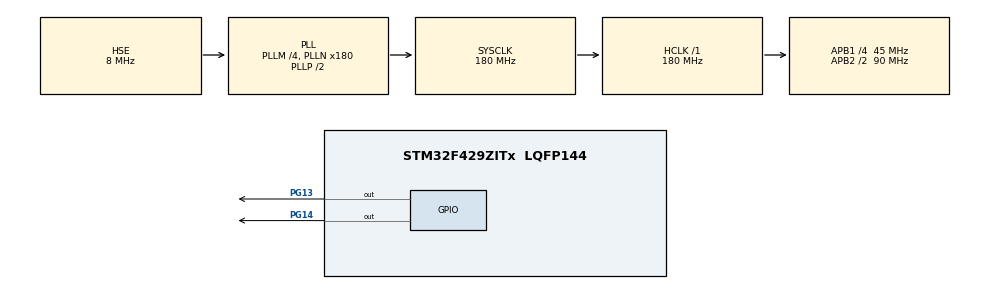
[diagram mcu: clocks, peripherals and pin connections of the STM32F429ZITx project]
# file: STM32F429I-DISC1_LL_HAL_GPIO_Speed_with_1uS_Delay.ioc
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Mcu.Family=STM32F4
Mcu.Name=STM32F429ZITx
Mcu.Package=LQFP144
NVIC.PriorityGroup=NVIC_PRIORITYGROUP_0
PG13.GPIO_Speed=GPIO_SPEED_FREQ_VERY_HIGH
PG13.Signal=GPIO_Output
PG14.GPIO_Speed=GPIO_SPEED_FREQ_VERY_HIGH
PG14.Signal=GPIO_Output
PH0/OSC_IN.Mode=HSE-External-Oscillator
PH0/OSC_IN.Signal=RCC_OSC_IN
PH1/OSC_OUT.Mode=HSE-External-Oscillator
PH1/OSC_OUT.Signal=RCC_OSC_OUT
ProjectManager.HeapSize=0x200
ProjectManager.StackSize=0x400
ProjectManager.TargetToolchain=STM32CubeIDE
RCC.48MHZClocksFreq_Value=51428571.428571425
RCC.AHBFreq_Value=180000000
RCC.APB1CLKDivider=RCC_HCLK_DIV4
RCC.APB1Freq_Value=45000000
RCC.APB1TimFreq_Value=90000000
RCC.APB2CLKDivider=RCC_HCLK_DIV2
RCC.APB2Freq_Value=90000000
RCC.APB2TimFreq_Value=180000000
RCC.CortexFreq_Value=180000000
RCC.HCLKFreq_Value=180000000
RCC.HSE_VALUE=8000000
RCC.HSI_VALUE=16000000
RCC.LSE_VALUE=32768
RCC.PLLM=4
RCC.PLLN=180
RCC.PLLQ=7
RCC.PLLSourceVirtual=RCC_PLLSOURCE_HSE
RCC.SYSCLKFreq_VALUE=180000000
RCC.SYSCLKSource=RCC_SYSCLKSOURCE_PLLCLK
RCC.VCOOutputFreq_Value=360000000
board=STM32F429I-DISC1

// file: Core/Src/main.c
/* USER CODE BEGIN Header */
/**
  ******************************************************************************
  * @file           : main.c
  * @brief          : Main program body
  ******************************************************************************
  * @attention
  *
  * <h2><center>&copy; Copyright (c) Victor.T Electronics.
  * All rights reserved.</center></h2>
  *
  * This software component is licensed by VT under BSD 3-Clause license,
  * the "License"; You may not use this file except in compliance with the
  * License. You may obtain a copy of the License at:
  *                        opensource.org/licenses/BSD-3-Clause
  *
  ******************************************************************************
  */
/* USER CODE END Header */
#include "main.h"

void SystemClock_Config(void);
static void MX_GPIO_Init(void);

int main(void)
{

  /* MCU Configuration--------------------------------------------------------*/

  /* Reset of all peripherals, Initializes the Flash interface and the Systick. */
  HAL_Init();

  /* Configure the system clock */
  SystemClock_Config();

  /* Initialize all configured peripherals */
  MX_GPIO_Init();

  /* Infinite loop */
  /* USER CODE BEGIN WHILE */
  while (1)
  {
	  // HAL
	  // 1.98Mhz / 510nS
	  // HAL_GPIO_TogglePin(GPIOG, GPIO_PIN_13); //

	  // LL
	  // 2.43Mhz / 412nS
	  // LL_GPIO_TogglePin(GPIOG, GPIO_PIN_13); //

	  // 15.1MHZ = LL/HAL / 66.8nS

	  GPIOG->BSRR = (1<<13); // SET
	  GPIOG->BSRR = (1<<29); // RESET

	  // approx 0 = 83nS, 1 = 184nS, 2 = 250nS, 3 = 317nS, 4 = 384nS, 5 = 450nS
	  // 6 = 517nS
//	  for(uint16_t nS_100 = 0; nS_100 < 1; nS_100++) // (1) (150 - 34n)S; (2) (217 - 34)nS; (3) (284 - 34)nS
//		  {}

	  // 1.018uS
	  for(uint16_t nS_100 = 0; nS_100 < 1; nS_100++) // (1) (150 - 34n)S; (2) (217 - 34)nS; (3) (284 - 34)nS
		  {}
	  for(uint16_t uS = 0; uS < 1; uS++)
	  {
		  for(uint16_t i = 0; i < 10; i++)
		  {}
	  }

    /* USER CODE END WHILE */

  }
}

void SystemClock_Config(void)
{
  RCC_OscInitTypeDef RCC_OscInitStruct = {0};
  RCC_ClkInitTypeDef RCC_ClkInitStruct = {0};

  /** Configure the main internal regulator output voltage
  */
  __HAL_RCC_PWR_CLK_ENABLE();
  __HAL_PWR_VOLTAGESCALING_CONFIG(PWR_REGULATOR_VOLTAGE_SCALE1);
  /** Initializes the RCC Oscillators according to the specified parameters
  * in the RCC_OscInitTypeDef structure.
  */
  RCC_OscInitStruct.OscillatorType = RCC_OSCILLATORTYPE_HSE;
  RCC_OscInitStruct.HSEState = RCC_HSE_ON;
  RCC_OscInitStruct.PLL.PLLState = RCC_PLL_ON;
  RCC_OscInitStruct.PLL.PLLSource = RCC_PLLSOURCE_HSE;
  RCC_OscInitStruct.PLL.PLLM = 4;
  RCC_OscInitStruct.PLL.PLLN = 180;
  RCC_OscInitStruct.PLL.PLLP = RCC_PLLP_DIV2;
  RCC_OscInitStruct.PLL.PLLQ = 7;
  if (HAL_RCC_OscConfig(&RCC_OscInitStruct) != HAL_OK)
  {
    Error_Handler();
  }
  /** Activate the Over-Drive mode
  */
  if (HAL_PWREx_EnableOverDrive() != HAL_OK)
  {
    Error_Handler();
  }
  /** Initializes the CPU, AHB and APB buses clocks
  */
  RCC_ClkInitStruct.ClockType = RCC_CLOCKTYPE_HCLK|RCC_CLOCKTYPE_SYSCLK
                              |RCC_CLOCKTYPE_PCLK1|RCC_CLOCKTYPE_PCLK2;
  RCC_ClkInitStruct.SYSCLKSource = RCC_SYSCLKSOURCE_PLLCLK;
  RCC_ClkInitStruct.AHBCLKDivider = RCC_SYSCLK_DIV1;
  RCC_ClkInitStruct.APB1CLKDivider = RCC_HCLK_DIV4;
  RCC_ClkInitStruct.APB2CLKDivider = RCC_HCLK_DIV2;

  if (HAL_RCC_ClockConfig(&RCC_ClkInitStruct, FLASH_LATENCY_5) != HAL_OK)
  {
    Error_Handler();
  }
}

static void MX_GPIO_Init(void)
{
  LL_GPIO_InitTypeDef GPIO_InitStruct = {0};

  /* GPIO Ports Clock Enable */
  LL_AHB1_GRP1_EnableClock(LL_AHB1_GRP1_PERIPH_GPIOH);
  LL_AHB1_GRP1_EnableClock(LL_AHB1_GRP1_PERIPH_GPIOG);

  /**/
  LL_GPIO_ResetOutputPin(GPIOG, LL_GPIO_PIN_13|LL_GPIO_PIN_14);

  /**/
  GPIO_InitStruct.Pin = LL_GPIO_PIN_13|LL_GPIO_PIN_14;
  GPIO_InitStruct.Mode = LL_GPIO_MODE_OUTPUT;
  GPIO_InitStruct.Speed = LL_GPIO_SPEED_FREQ_VERY_HIGH;
  GPIO_InitStruct.OutputType = LL_GPIO_OUTPUT_PUSHPULL;
  GPIO_InitStruct.Pull = LL_GPIO_PULL_NO;
  LL_GPIO_Init(GPIOG, &GPIO_InitStruct);

}

void Error_Handler(void)
{
}

/************************ (C) COPYRIGHT STMicroelectronics *****END OF FILE****/
